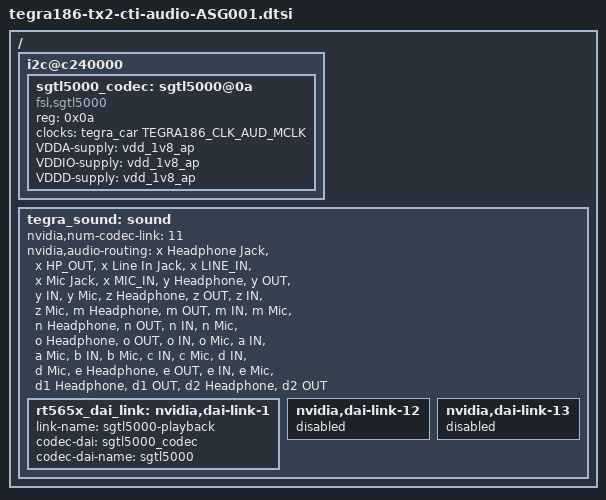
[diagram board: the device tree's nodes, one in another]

/* Astro FSL SGTL5000 Audio code support */

#include <dt-bindings/types.h>
#include <dt-bindings/gpio/tegra186-gpio.h>

/ {
        
    i2c@c240000 {
        sgtl5000_codec: sgtl5000@0a {
            status = "okay";
            compatible = "fsl,sgtl5000";
            reg = <0x0a>;
            clocks=<&tegra_car TEGRA186_CLK_AUD_MCLK>;
            VDDA-supply=<&vdd_1v8_ap>;
            VDDIO-supply = <&vdd_1v8_ap>;
            VDDD-supply = <&vdd_1v8_ap>;
        }; 
    };
       
	tegra_sound: sound {
		nvidia,num-codec-link = <11>;
		status = "okay";
        
		nvidia,audio-routing =
            "x Headphone Jack", "x HP_OUT",
            "x Line In Jack", "x LINE_IN", 
            "x Mic Jack", "x MIC_IN",
			"y Headphone",		"y OUT",
			"y IN",			"y Mic",
			"z Headphone",		"z OUT",
			"z IN",			"z Mic",
			"m Headphone",		"m OUT",
			"m IN",			"m Mic",
			"n Headphone",		"n OUT",
			"n IN",			"n Mic",
			"o Headphone",		"o OUT",
			"o IN",			"o Mic",
			"a IN",			"a Mic",
			"b IN",			"b Mic",
			"c IN",			"c Mic",
			"d IN",			"d Mic",
			"e Headphone",		"e OUT",
			"e IN",			"e Mic",
			"d1 Headphone",		"d1 OUT",
			"d2 Headphone",		"d2 OUT";

            
		rt565x_dai_link: nvidia,dai-link-1 {
			link-name = "sgtl5000-playback";
			codec-dai = <&sgtl5000_codec>;
			codec-dai-name = "sgtl5000";
			status = "okay";
		};
		nvidia,dai-link-12 {
			status = "disabled";
		};
		nvidia,dai-link-13 {
			status = "disabled";
        };
	};
};
